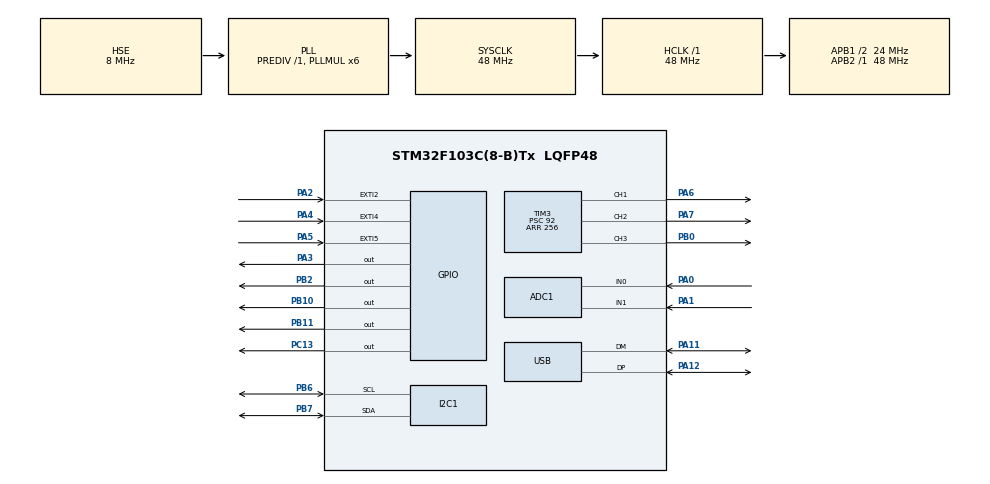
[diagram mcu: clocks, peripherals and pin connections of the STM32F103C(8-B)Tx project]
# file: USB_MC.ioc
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ADC1.Channel-1\#ChannelRegularConversion=ADC_CHANNEL_0
ADC1.Channel-2\#ChannelRegularConversion=ADC_CHANNEL_1
ADC1.ContinuousConvMode=ENABLE
ADC1.DataAlign=ADC_DATAALIGN_RIGHT
ADC1.EnableRegularConversion=ENABLE
ADC1.NbrOfConversion=2
ADC1.NbrOfConversionFlag=1
ADC1.Rank-1\#ChannelRegularConversion=1
ADC1.Rank-2\#ChannelRegularConversion=2
ADC1.SamplingTime-1\#ChannelRegularConversion=ADC_SAMPLETIME_1CYCLE_5
ADC1.SamplingTime-2\#ChannelRegularConversion=ADC_SAMPLETIME_1CYCLE_5
ADC1.master=1
Dma.ADC1.0.Direction=DMA_PERIPH_TO_MEMORY
Dma.ADC1.0.Instance=DMA1_Channel1
Dma.ADC1.0.MemDataAlignment=DMA_MDATAALIGN_HALFWORD
Dma.ADC1.0.MemInc=DMA_MINC_ENABLE
Dma.ADC1.0.Mode=DMA_CIRCULAR
Dma.ADC1.0.PeriphDataAlignment=DMA_PDATAALIGN_HALFWORD
Dma.ADC1.0.PeriphInc=DMA_PINC_DISABLE
Dma.ADC1.0.Priority=DMA_PRIORITY_MEDIUM
Dma.Request0=ADC1
Mcu.Family=STM32F1
Mcu.Name=STM32F103C(8-B)Tx
Mcu.Package=LQFP48
NVIC.DMA1_Channel1_IRQn=true\:0\:0\:false\:false\:true\:false\:true
NVIC.EXTI2_IRQn=true\:0\:0\:false\:false\:true\:true\:true
NVIC.EXTI4_IRQn=true\:0\:0\:false\:false\:true\:true\:true
NVIC.EXTI9_5_IRQn=true\:0\:0\:false\:false\:true\:true\:true
NVIC.PriorityGroup=NVIC_PRIORITYGROUP_4
NVIC.TIM4_IRQn=true\:0\:0\:false\:false\:true\:true\:true
NVIC.USB_LP_CAN1_RX0_IRQn=true\:0\:0\:false\:false\:true\:false\:true
PA0-WKUP.Signal=ADCx_IN0
PA1.Signal=ADCx_IN1
PA11.Mode=Device
PA11.Signal=USB_DM
PA12.Mode=Device
PA12.Signal=USB_DP
PA13.Mode=Serial_Wire
PA13.Signal=SYS_JTMS-SWDIO
PA14.Mode=Serial_Wire
PA14.Signal=SYS_JTCK-SWCLK
PA2.GPIO_ModeDefaultEXTI=GPIO_MODE_IT_RISING_FALLING
PA2.GPIO_PuPd=GPIO_PULLDOWN
PA2.Signal=GPXTI2
PA3.Signal=GPIO_Output
PA4.GPIO_ModeDefaultEXTI=GPIO_MODE_IT_RISING_FALLING
PA4.GPIO_PuPd=GPIO_PULLDOWN
PA4.Signal=GPXTI4
PA5.GPIO_ModeDefaultEXTI=GPIO_MODE_IT_RISING_FALLING
PA5.GPIO_PuPd=GPIO_PULLDOWN
PA5.Signal=GPXTI5
PA6.GPIO_Speed=GPIO_SPEED_FREQ_HIGH
PA6.Signal=S_TIM3_CH1
PA7.GPIO_Speed=GPIO_SPEED_FREQ_HIGH
PA7.Signal=S_TIM3_CH2
PB0.GPIO_Speed=GPIO_SPEED_FREQ_HIGH
PB0.Signal=S_TIM3_CH3
PB10.PinState=GPIO_PIN_RESET
PB10.Signal=GPIO_Output
PB11.PinState=GPIO_PIN_RESET
PB11.Signal=GPIO_Output
PB2.Signal=GPIO_Output
PB6.Mode=I2C
PB6.Signal=I2C1_SCL
PB7.Mode=I2C
PB7.Signal=I2C1_SDA
PC13-TAMPER-RTC.GPIO_Speed=GPIO_SPEED_FREQ_LOW
PC13-TAMPER-RTC.PinState=GPIO_PIN_SET
PC13-TAMPER-RTC.Signal=GPIO_Output
PD0-OSC_IN.Mode=HSE-External-Oscillator
PD0-OSC_IN.Signal=RCC_OSC_IN
PD1-OSC_OUT.Mode=HSE-External-Oscillator
PD1-OSC_OUT.Signal=RCC_OSC_OUT
ProjectManager.HeapSize=0x200
ProjectManager.StackSize=0x400
ProjectManager.TargetToolchain=Makefile
RCC.ADCPresc=RCC_ADCPCLK2_DIV4
RCC.AHBFreq_Value=48000000
RCC.APB1CLKDivider=RCC_HCLK_DIV2
RCC.APB1Freq_Value=24000000
RCC.APB1TimFreq_Value=48000000
RCC.APB2Freq_Value=48000000
RCC.APB2TimFreq_Value=48000000
RCC.HCLKFreq_Value=48000000
RCC.PLLMUL=RCC_PLL_MUL6
RCC.SYSCLKFreq_VALUE=48000000
RCC.SYSCLKSource=RCC_SYSCLKSOURCE_PLLCLK
RCC.USBFreq_Value=48000000
SH.ADCx_IN0.0=ADC1_IN0,IN0
SH.ADCx_IN1.0=ADC1_IN1,IN1
SH.S_TIM3_CH1.0=TIM3_CH1,PWM Generation1 CH1
SH.S_TIM3_CH2.0=TIM3_CH2,PWM Generation2 CH2
SH.S_TIM3_CH3.0=TIM3_CH3,PWM Generation3 CH3
TIM3.Channel-PWM\ Generation1\ CH1=TIM_CHANNEL_1
TIM3.Channel-PWM\ Generation2\ CH2=TIM_CHANNEL_2
TIM3.Channel-PWM\ Generation3\ CH3=TIM_CHANNEL_3
TIM3.Period=256
TIM3.Prescaler=92
TIM4.Channel-Output\ Compare1\ No\ Output=TIM_CHANNEL_1
TIM4.Period=9
TIM4.Prescaler=47999
USB_DEVICE.CLASS_NAME_FS=CUSTOM_HID
USB_DEVICE.USBD_CUSTOM_HID_REPORT_DESC_SIZE=108
USB_DEVICE.VirtualMode=CustomHid
USB_DEVICE.VirtualModeFS=Custom_Hid_FS
VP_TIM3_VS_ClockSourceINT.Mode=Internal
VP_TIM4_VS_ClockSourceINT.Mode=Internal
VP_TIM4_VS_no_output1.Mode=Output Compare1 No Output
VP_USB_DEVICE_VS_USB_DEVICE_CUSTOM_HID_FS.Mode=CUSTOM_HID_FS
board=custom

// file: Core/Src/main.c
/* USER CODE BEGIN Header */
/**
  ******************************************************************************
  * @file           : main.c
  * @brief          : Main program body
  ******************************************************************************
  * @attention
  *
  * <h2><center>&copy; Copyright (c) 2019 STMicroelectronics.
  * All rights reserved.</center></h2>
  *
  * This software component is licensed by ST under Ultimate Liberty license
  * SLA0044, the "License"; You may not use this file except in compliance with
  * the License. You may obtain a copy of the License at:
  *                             www.st.com/SLA0044
  *
  ******************************************************************************
  */
/* USER CODE END Header */

#include "main.h"
#include "adc.h"
#include "dma.h"
#include "i2c.h"
#include "tim.h"
#include "usb_device.h"
#include "gpio.h"

void SystemClock_Config(void);

int main(void)
{

  /* MCU Configuration--------------------------------------------------------*/

  /* Reset of all peripherals, Initializes the Flash interface and the Systick. */
  HAL_Init();

  /* Configure the system clock */
  SystemClock_Config();

  /* Initialize all configured peripherals */
  MX_GPIO_Init();
  MX_DMA_Init();
  MX_USB_DEVICE_Init();
  MX_TIM3_Init();
  MX_ADC1_Init();
  MX_TIM4_Init();
  MX_I2C1_Init();
  /* USER CODE BEGIN 2 */

	I2C_launchBH1750();

	HAL_TIM_Base_Start_IT(&htim3);
	HAL_TIM_Base_Start_IT(&htim4);

	HAL_TIM_PWM_Start(&htim3, TIM_CHANNEL_1);
	HAL_TIM_PWM_Start(&htim3, TIM_CHANNEL_2);
	HAL_TIM_PWM_Start(&htim3, TIM_CHANNEL_3);

	HAL_ADC_Start_DMA(&hadc1, (uint32_t*) &ADC_Data, 2);

  /* USER CODE END 2 */

  /* Infinite loop */
  while (1)
  {

  }
}

void SystemClock_Config(void)
{
  RCC_OscInitTypeDef RCC_OscInitStruct = {0};
  RCC_ClkInitTypeDef RCC_ClkInitStruct = {0};
  RCC_PeriphCLKInitTypeDef PeriphClkInit = {0};

  /** Initializes the CPU, AHB and APB busses clocks
  */
  RCC_OscInitStruct.OscillatorType = RCC_OSCILLATORTYPE_HSE;
  RCC_OscInitStruct.HSEState = RCC_HSE_ON;
  RCC_OscInitStruct.HSEPredivValue = RCC_HSE_PREDIV_DIV1;
  RCC_OscInitStruct.HSIState = RCC_HSI_ON;
  RCC_OscInitStruct.PLL.PLLState = RCC_PLL_ON;
  RCC_OscInitStruct.PLL.PLLSource = RCC_PLLSOURCE_HSE;
  RCC_OscInitStruct.PLL.PLLMUL = RCC_PLL_MUL6;
  if (HAL_RCC_OscConfig(&RCC_OscInitStruct) != HAL_OK)
  {
    Error_Handler();
  }
  /** Initializes the CPU, AHB and APB busses clocks
  */
  RCC_ClkInitStruct.ClockType = RCC_CLOCKTYPE_HCLK|RCC_CLOCKTYPE_SYSCLK
                              |RCC_CLOCKTYPE_PCLK1|RCC_CLOCKTYPE_PCLK2;
  RCC_ClkInitStruct.SYSCLKSource = RCC_SYSCLKSOURCE_PLLCLK;
  RCC_ClkInitStruct.AHBCLKDivider = RCC_SYSCLK_DIV1;
  RCC_ClkInitStruct.APB1CLKDivider = RCC_HCLK_DIV2;
  RCC_ClkInitStruct.APB2CLKDivider = RCC_HCLK_DIV1;

  if (HAL_RCC_ClockConfig(&RCC_ClkInitStruct, FLASH_LATENCY_1) != HAL_OK)
  {
    Error_Handler();
  }
  PeriphClkInit.PeriphClockSelection = RCC_PERIPHCLK_ADC|RCC_PERIPHCLK_USB;
  PeriphClkInit.AdcClockSelection = RCC_ADCPCLK2_DIV4;
  PeriphClkInit.UsbClockSelection = RCC_USBCLKSOURCE_PLL;
  if (HAL_RCCEx_PeriphCLKConfig(&PeriphClkInit) != HAL_OK)
  {
    Error_Handler();
  }
}

void Error_Handler(void)
{
}

/************************ (C) COPYRIGHT STMicroelectronics *****END OF FILE****/
